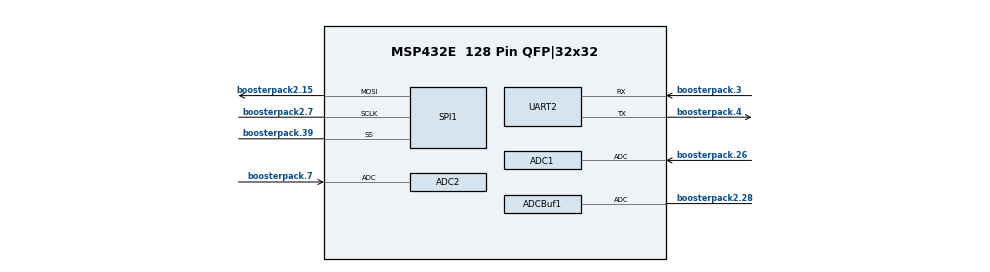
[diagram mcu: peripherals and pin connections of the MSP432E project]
/**
 * @cliArgs --board "/ti/boards/MSP_EXP432E401Y" --device "MSP432E" --part "MSP432E401YTPDT" --package "128 Pin QFP|32x32" --product "simplelink_msp432e4_sdk@4.20.00.12"
 * @versions {"tool":"1.21.0+3721"}
 */

/**
 * Import the modules used in this configuration.
 */
const ADC     = scripting.addModule("/ti/drivers/ADC", {}, false);
const ADC1    = ADC.addInstance();
const ADC2    = ADC.addInstance();
const ADCBuf  = scripting.addModule("/ti/drivers/ADCBuf", {}, false);
const ADCBuf1 = ADCBuf.addInstance();
const GPIO    = scripting.addModule("/ti/drivers/GPIO");
const GPIO1   = GPIO.addInstance();
const GPIO2   = GPIO.addInstance();
const GPIO3   = GPIO.addInstance();
const GPIO4   = GPIO.addInstance();
const GPIO5   = GPIO.addInstance();
const GPIO6   = GPIO.addInstance();
const GPIO7   = GPIO.addInstance();
const GPIO8   = GPIO.addInstance();
const Power   = scripting.addModule("/ti/drivers/Power");
const RTOS    = scripting.addModule("/ti/drivers/RTOS");
const SPI     = scripting.addModule("/ti/drivers/SPI", {}, false);
const SPI1    = SPI.addInstance();
const Timer   = scripting.addModule("/ti/drivers/Timer", {}, false);
const Timer1  = Timer.addInstance();
const Timer2  = Timer.addInstance();
const UART    = scripting.addModule("/ti/drivers/UART");
const UART1   = UART.addInstance();
const UART2   = UART.addInstance();

/**
 * Write custom configuration values to the imported modules.
 */
ADC1.$name              = "CONFIG_ADC_0";
ADC1.adc.adcPin.$assign = "boosterpack.26";

ADC2.$name              = "CONFIG_ADC_1";
ADC2.adc.adcPin.$assign = "boosterpack.7";

ADCBuf1.$name                              = "CONFIG_ADCBUF_0";
ADCBuf1.sequencer0.$name                   = "ti_drivers_adcbuf_ADCBufSeqMSP432E40";
ADCBuf1.sequencer0.channel0.$name          = "ADCBUF_CHANNEL_0";
ADCBuf1.sequencer0.channel0.adcPin.$assign = "boosterpack2.28";

GPIO1.$name     = "CONFIG_GPIO_LED_0";
GPIO1.pull      = "Pull Up";
GPIO1.$hardware = system.deviceData.board.components.D1;

GPIO2.$name     = "CONFIG_GPIO_LED_1";
GPIO2.$hardware = system.deviceData.board.components.D2;

GPIO3.$name     = "CONFIG_GPIO_LED_2";
GPIO3.$hardware = system.deviceData.board.components.D3;

GPIO4.$name     = "CONFIG_GPIO_LED_3";
GPIO4.$hardware = system.deviceData.board.components.D4;

GPIO5.$name = "CONFIG_GPIO_PK5";
GPIO5.mode  = "Output";

GPIO6.mode               = "Output";
GPIO6.$name              = "CONFIG_GPIO_PD4";
GPIO6.initialOutputState = "High";

GPIO7.$name     = "CONFIG_GPIO_BUTTON_0";
GPIO7.$hardware = system.deviceData.board.components.USR_SW1;

GPIO8.$name     = "CONFIG_GPIO_BUTTON_1";
GPIO8.$hardware = system.deviceData.board.components.USR_SW2;


SPI1.$name               = "CONFIG_SPI_0";
SPI1.mode                = "Four Pin SS Active Low";
SPI1.spi.$assign         = "SSI3";
SPI1.spi.sclkPin.$assign = "boosterpack2.7";
SPI1.spi.mosiPin.$assign = "boosterpack2.15";
SPI1.spi.ssPin.$assign   = "boosterpack.39";

Timer1.$name             = "CONFIG_TIMER_0";
Timer1.timerType         = "32 Bits";
Timer1.interruptPriority = "1";

Timer2.$name             = "CONFIG_TIMER_1";
Timer2.timerType         = "32 Bits";
Timer2.interruptPriority = "1";

UART1.$name     = "CONFIG_UART_0";
UART1.$hardware = system.deviceData.board.components.XDS110UART;

UART2.$name              = "CONFIG_UART_7";
UART2.uart.$assign       = "UART7";
UART2.uart.txPin.$assign = "boosterpack.4";
UART2.uart.rxPin.$assign = "boosterpack.3";

/**
 * Pinmux solution for unlocked pins/peripherals. This ensures that minor changes to the automatic solver in a future
 * version of the tool will not impact the pinmux you originally saw.  These lines can be completely deleted in order to
 * re-solve from scratch.
 */
ADC1.adc.$suggestSolution                      = "ADC0";
ADC2.adc.$suggestSolution                      = "ADC0";
ADCBuf1.timer.$suggestSolution                 = "Timer3";
ADCBuf1.adc.$suggestSolution                   = "ADC1";
ADCBuf1.sequencer0.dmaChannel.$suggestSolution = "UDMA_CH24";
GPIO1.gpioPin.$suggestSolution                 = "expansion.87";
GPIO2.gpioPin.$suggestSolution                 = "expansion.85";
GPIO3.gpioPin.$suggestSolution                 = "expansion.64";
GPIO4.gpioPin.$suggestSolution                 = "expansion.66";
GPIO5.gpioPin.$suggestSolution                 = "boosterpack.14";
GPIO6.gpioPin.$suggestSolution                 = "boosterpack.15";
GPIO7.gpioPin.$suggestSolution                 = "expansion.82";
GPIO8.gpioPin.$suggestSolution                 = "expansion.84";
RTOS.timer0.resource.$suggestSolution          = "Timer0";
SPI1.spi.misoPin.$suggestSolution              = "boosterpack2.14";
SPI1.spi.dmaRxChannel.$suggestSolution         = "UDMA_CH14";
SPI1.spi.dmaTxChannel.$suggestSolution         = "UDMA_CH15";
Timer1.timer.$suggestSolution                  = "Timer2";
Timer2.timer.$suggestSolution                  = "Timer1";
UART1.uart.$suggestSolution                    = "UART0";
UART1.uart.txPin.$suggestSolution              = "expansion.76";
UART1.uart.rxPin.$suggestSolution              = "expansion.74";
